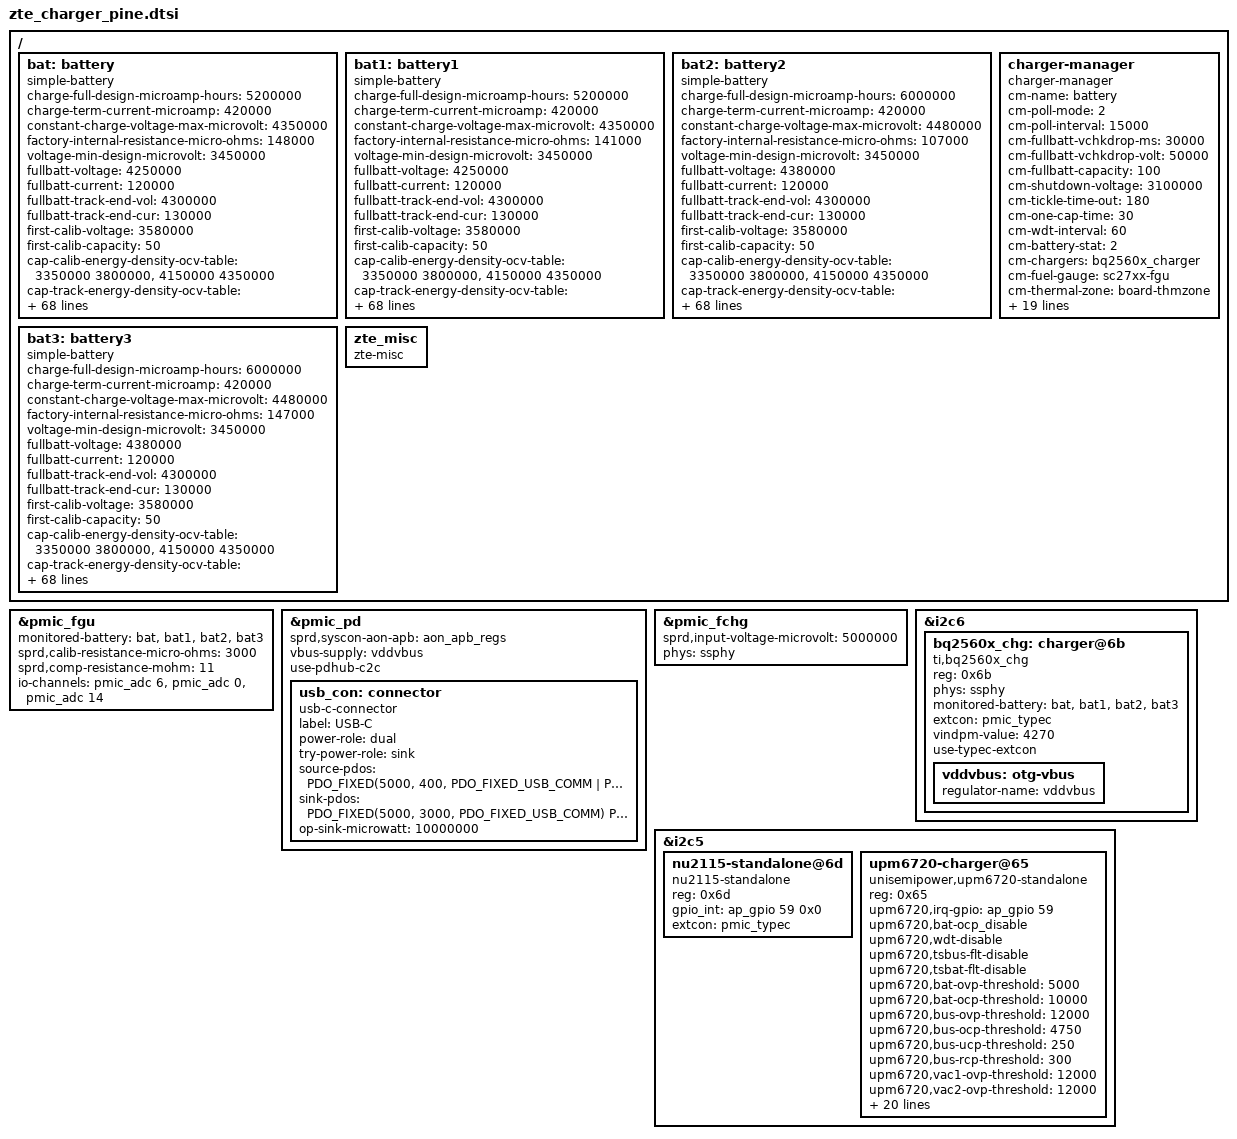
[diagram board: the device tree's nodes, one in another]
#include <dt-bindings/usb/pd.h>
#include <dt-bindings/mfd/sprd,ump9620-regs.h>
#include <dt-bindings/mfd/sprd,ump9620-mask.h>

/ {
	bat: battery {
		compatible = "simple-battery";
		charge-full-design-microamp-hours = <3690000>;
		charge-term-current-microamp = <120000>;
		constant-charge-voltage-max-microvolt = <4400000>;
		factory-internal-resistance-micro-ohms = <130000>;
		voltage-min-design-microvolt = <3450000>;
		fullbatt-voltage = <4350000>;
		fullbatt-current = <120000>;
		fullbatt-track-end-vol = <4345000>;
		fullbatt-track-end-cur = <130000>;
		first-calib-voltage = <3630000>;
		first-calib-capacity = <50>;

		cap-calib-energy-density-ocv-table = <3350000 3800000>, <4150000 4350000>;
		cap-track-energy-density-ocv-table = <3400000 3722000>;

		ocv-capacity-celsius = <20>;
		ocv-capacity-table-0 = <4380000 100>, <4317000 95>, <4258000 90>,
					<4200000 85>, <4145000 80>, <4092000 75>,
					<4047000 70>, <3990000 65>, <3955000 60>,
					<3900000 55>, <3861000 50>, <3834000 45>,
					<3813000 40>, <3796000 35>, <3783000 30>,
					<3770000 25>, <3752000 20>, <3730000 15>,
					<3698000 10>, <3687000 5>, <3400000 0>;
		voltage-temp-table = <1095000 800>, <986000 850>, <878000 900>,
					<775000 950>, <678000 1000>, <590000 1050>,
					<510000 1100>, <440000 1150>, <378000 1200>,
					<324000 1250>, <278000 1300>, <238000 1350>,
					<204000 1400>, <175000 1450>, <150000 1500>,
					<129000 1550>, <111000 1600>, <96000 1650>;
		capacity-temp-table = <45 100>, <25 100>, <10 98>, <0 93>, <(-10) 85>, <(-20) 64>;
		resistance-temp-table = <45 77>, <25 100>, <10 546>, <0 769>, <(-10) 892>, <(-20) 923>;

/*
		battery-internal-resistance-celsius = <(-20)>, <(-10)>, <0>, <10>,
			<25>, <35>, <45>, <55>;
		battery-internal-resistance-table-0 = <1224>, <1224>, <1140>,
			<1084>, <1034>, <1001>, <994>, <992>, <992>, <992>,
			<996>, <1002>, <1010>, <1024>, <1045>, <1072>, <1180>,
			<1393>, <1756>, <2461>, <4272>;
		battery-internal-resistance-table-1 = <893>, <893>, <818>, <767>,
			<743>, <705>, <685>, <684>, <678>, <675>, <672>, <673>,
			<679>, <691>, <709>, <734>, <765>, <799>, <839>, <899>,
			<1092>;
		battery-internal-resistance-table-2 = <407>, <407>, <402>, <423>,
			<429>, <428>, <409>, <416>, <408>, <395>, <390>, <390>,
			<393>, <398>, <405>, <416>, <431>, <452>, <492>, <585>,
			<730>;
		battery-internal-resistance-table-3 = <381>, <381>, <378>, <371>,
			<366>, <374>, <358>, <364>, <349>, <332>, <327>, <329>,
			<334>, <340>, <350>, <366>, <386>, <417>, <475>, <585>,
			<771>;
		battery-internal-resistance-table-4 = <182>, <182>, <179>, <179>,
			<179>, <181>, <182>, <195>, <194>, <173>, <164>, <164>,
			<167>, <171>, <175>, <174>, <172>, <179>, <187>, <244>,
			<311>;
		battery-internal-resistance-table-5 = <168>, <168>, <175>, <172>,
			<171>, <171>, <173>, <184>, <176>, <153>, <147>, <147>,
			<150>, <153>, <156>, <152>, <149>, <154>, <158>, <206>,
			<255>;
		battery-internal-resistance-table-6 = <123>, <123>, <122>, <122>,
			<123>, <126>, <130>, <138>, <143>, <120>, <115>, <116>,
			<119>, <124>, <129>, <120>, <117>, <119>, <117>, <139>,
			<156>;
		battery-internal-resistance-table-7 = <106>, <106>, <106>, <106>,
			<108>, <110>, <113>, <119>, <128>, <107>, <104>, <105>,
			<108>, <112>, <117>, <107>, <106>, <107>, <105>, <127>,
			<140>;
		battery-internal-resistance-ocv-table = <4339000>, <4276000>,
			<4221000>, <4169000>, <4118000>, <4072000>, <4022000>,
			<3983000>, <3942000>, <3892000>, <3857000>, <3833000>,
			<3813000>, <3797000>, <3783000>, <3766000>, <3746000>,
			<3723000>, <3693000>, <3680000>, <3439000>;
*/

		charge-sdp-current-microamp = <500000 500000>;
		charge-dcp-current-microamp = <1150000 3000000>;
		charge-cdp-current-microamp = <1150000 1150000>;
		charge-unknown-current-microamp = <500000 500000>;

		dcp-jeita-temp-table = <1000 1030 0 4400000>, <1150 1180 700000 4400000>,
			<1450 1420 1150000 4400000>, <1600 1570 700000 4100000>;
		sdp-jeita-temp-table = <1000 1030 0 4400000>, <1150 1180 500000 4400000>,
			<1450 1420 500000 4400000>, <1600 1570 500000 4100000>;
		cdp-jeita-temp-table = <1000 1030 0 4400000>, <1150 1180 700000 4400000>,
			<1450 1420 1150000 4400000>, <1600 1570 700000 4100000>;
		unknown-jeita-temp-table = <1000 1030 0 4400000>, <1150 1180 500000 4400000>,
			<1450 1420 500000 4400000>, <1600 1570 500000 4100000>;
		force-jeita-status = <2>;
	};

	bat1: battery1 {
		compatible = "simple-battery";
		charge-full-design-microamp-hours = <3690000>;
		charge-term-current-microamp = <120000>;
		constant-charge-voltage-max-microvolt = <4400000>;
		factory-internal-resistance-micro-ohms = <130000>;
		voltage-min-design-microvolt = <3450000>;
		fullbatt-voltage = <4350000>;
		fullbatt-current = <120000>;
		fullbatt-track-end-vol = <4345000>;
		fullbatt-track-end-cur = <130000>;
		first-calib-voltage = <3630000>;
		first-calib-capacity = <50>;

		cap-calib-energy-density-ocv-table = <3350000 3800000>, <4150000 4350000>;
		cap-track-energy-density-ocv-table = <3400000 3722000>;

		ocv-capacity-celsius = <20>;
		ocv-capacity-table-0 = <4380000 100>, <4317000 95>, <4258000 90>,
					<4200000 85>, <4145000 80>, <4092000 75>,
					<4047000 70>, <3990000 65>, <3955000 60>,
					<3900000 55>, <3861000 50>, <3834000 45>,
					<3813000 40>, <3796000 35>, <3783000 30>,
					<3770000 25>, <3752000 20>, <3730000 15>,
					<3698000 10>, <3687000 5>, <3400000 0>;
		voltage-temp-table = <1095000 800>, <986000 850>, <878000 900>,
					<775000 950>, <678000 1000>, <590000 1050>,
					<510000 1100>, <440000 1150>, <378000 1200>,
					<324000 1250>, <278000 1300>, <238000 1350>,
					<204000 1400>, <175000 1450>, <150000 1500>,
					<129000 1550>, <111000 1600>, <96000 1650>;
		capacity-temp-table = <45 100>, <25 100>, <10 98>, <0 93>, <(-10) 85>, <(-20) 64>;
		resistance-temp-table = <45 77>, <25 100>, <10 546>, <0 769>, <(-10) 892>, <(-20) 923>;

/*
		battery-internal-resistance-celsius = <(-20)>, <(-10)>, <0>, <10>,
			<25>, <35>, <45>, <55>;
		battery-internal-resistance-table-0 = <1224>, <1224>, <1140>,
			<1084>, <1034>, <1001>, <994>, <992>, <992>, <992>,
			<996>, <1002>, <1010>, <1024>, <1045>, <1072>, <1180>,
			<1393>, <1756>, <2461>, <4272>;
		battery-internal-resistance-table-1 = <893>, <893>, <818>, <767>,
			<743>, <705>, <685>, <684>, <678>, <675>, <672>, <673>,
			<679>, <691>, <709>, <734>, <765>, <799>, <839>, <899>,
			<1092>;
		battery-internal-resistance-table-2 = <407>, <407>, <402>, <423>,
			<429>, <428>, <409>, <416>, <408>, <395>, <390>, <390>,
			<393>, <398>, <405>, <416>, <431>, <452>, <492>, <585>,
			<730>;
		battery-internal-resistance-table-3 = <381>, <381>, <378>, <371>,
			<366>, <374>, <358>, <364>, <349>, <332>, <327>, <329>,
			<334>, <340>, <350>, <366>, <386>, <417>, <475>, <585>,
			<771>;
		battery-internal-resistance-table-4 = <182>, <182>, <179>, <179>,
			<179>, <181>, <182>, <195>, <194>, <173>, <164>, <164>,
			<167>, <171>, <175>, <174>, <172>, <179>, <187>, <244>,
			<311>;
		battery-internal-resistance-table-5 = <168>, <168>, <175>, <172>,
			<171>, <171>, <173>, <184>, <176>, <153>, <147>, <147>,
			<150>, <153>, <156>, <152>, <149>, <154>, <158>, <206>,
			<255>;
		battery-internal-resistance-table-6 = <123>, <123>, <122>, <122>,
			<123>, <126>, <130>, <138>, <143>, <120>, <115>, <116>,
			<119>, <124>, <129>, <120>, <117>, <119>, <117>, <139>,
			<156>;
		battery-internal-resistance-table-7 = <106>, <106>, <106>, <106>,
			<108>, <110>, <113>, <119>, <128>, <107>, <104>, <105>,
			<108>, <112>, <117>, <107>, <106>, <107>, <105>, <127>,
			<140>;
		battery-internal-resistance-ocv-table = <4339000>, <4276000>,
			<4221000>, <4169000>, <4118000>, <4072000>, <4022000>,
			<3983000>, <3942000>, <3892000>, <3857000>, <3833000>,
			<3813000>, <3797000>, <3783000>, <3766000>, <3746000>,
			<3723000>, <3693000>, <3680000>, <3439000>;
*/

		charge-sdp-current-microamp = <500000 500000>;
		charge-dcp-current-microamp = <1150000 3000000>;
		charge-cdp-current-microamp = <1150000 1150000>;
		charge-unknown-current-microamp = <500000 500000>;

		dcp-jeita-temp-table = <1000 1030 0 4400000>, <1150 1180 700000 4400000>,
			<1450 1420 1150000 4400000>, <1600 1570 700000 4100000>;
		sdp-jeita-temp-table = <1000 1030 0 4400000>, <1150 1180 500000 4400000>,
			<1450 1420 500000 4400000>, <1600 1570 500000 4100000>;
		cdp-jeita-temp-table = <1000 1030 0 4400000>, <1150 1180 700000 4400000>,
			<1450 1420 1150000 4400000>, <1600 1570 700000 4100000>;
		unknown-jeita-temp-table = <1000 1030 0 4400000>, <1150 1180 500000 4400000>,
			<1450 1420 500000 4400000>, <1600 1570 500000 4100000>;
		force-jeita-status = <2>;
	};

	bat2: battery2 {
		compatible = "simple-battery";
		charge-full-design-microamp-hours = <3690000>;
		charge-term-current-microamp = <120000>;
		constant-charge-voltage-max-microvolt = <4400000>;
		factory-internal-resistance-micro-ohms = <130000>;
		voltage-min-design-microvolt = <3450000>;
		fullbatt-voltage = <4350000>;
		fullbatt-current = <120000>;
		fullbatt-track-end-vol = <4345000>;
		fullbatt-track-end-cur = <130000>;
		first-calib-voltage = <3630000>;
		first-calib-capacity = <50>;

		cap-calib-energy-density-ocv-table = <3350000 3800000>, <4150000 4350000>;
		cap-track-energy-density-ocv-table = <3400000 3722000>;

		ocv-capacity-celsius = <20>;
		ocv-capacity-table-0 = <4380000 100>, <4317000 95>, <4258000 90>,
					<4200000 85>, <4145000 80>, <4092000 75>,
					<4047000 70>, <3990000 65>, <3955000 60>,
					<3900000 55>, <3861000 50>, <3834000 45>,
					<3813000 40>, <3796000 35>, <3783000 30>,
					<3770000 25>, <3752000 20>, <3730000 15>,
					<3698000 10>, <3687000 5>, <3400000 0>;
		voltage-temp-table = <1095000 800>, <986000 850>, <878000 900>,
					<775000 950>, <678000 1000>, <590000 1050>,
					<510000 1100>, <440000 1150>, <378000 1200>,
					<324000 1250>, <278000 1300>, <238000 1350>,
					<204000 1400>, <175000 1450>, <150000 1500>,
					<129000 1550>, <111000 1600>, <96000 1650>;
		capacity-temp-table = <45 100>, <25 100>, <10 98>, <0 93>, <(-10) 85>, <(-20) 64>;
		resistance-temp-table = <45 77>, <25 100>, <10 546>, <0 769>, <(-10) 892>, <(-20) 923>;

/*
		battery-internal-resistance-celsius = <(-20)>, <(-10)>, <0>, <10>,
			<25>, <35>, <45>, <55>;
		battery-internal-resistance-table-0 = <1224>, <1224>, <1140>,
			<1084>, <1034>, <1001>, <994>, <992>, <992>, <992>,
			<996>, <1002>, <1010>, <1024>, <1045>, <1072>, <1180>,
			<1393>, <1756>, <2461>, <4272>;
		battery-internal-resistance-table-1 = <893>, <893>, <818>, <767>,
			<743>, <705>, <685>, <684>, <678>, <675>, <672>, <673>,
			<679>, <691>, <709>, <734>, <765>, <799>, <839>, <899>,
			<1092>;
		battery-internal-resistance-table-2 = <407>, <407>, <402>, <423>,
			<429>, <428>, <409>, <416>, <408>, <395>, <390>, <390>,
			<393>, <398>, <405>, <416>, <431>, <452>, <492>, <585>,
			<730>;
		battery-internal-resistance-table-3 = <381>, <381>, <378>, <371>,
			<366>, <374>, <358>, <364>, <349>, <332>, <327>, <329>,
			<334>, <340>, <350>, <366>, <386>, <417>, <475>, <585>,
			<771>;
		battery-internal-resistance-table-4 = <182>, <182>, <179>, <179>,
			<179>, <181>, <182>, <195>, <194>, <173>, <164>, <164>,
			<167>, <171>, <175>, <174>, <172>, <179>, <187>, <244>,
			<311>;
		battery-internal-resistance-table-5 = <168>, <168>, <175>, <172>,
			<171>, <171>, <173>, <184>, <176>, <153>, <147>, <147>,
			<150>, <153>, <156>, <152>, <149>, <154>, <158>, <206>,
			<255>;
		battery-internal-resistance-table-6 = <123>, <123>, <122>, <122>,
			<123>, <126>, <130>, <138>, <143>, <120>, <115>, <116>,
			<119>, <124>, <129>, <120>, <117>, <119>, <117>, <139>,
			<156>;
		battery-internal-resistance-table-7 = <106>, <106>, <106>, <106>,
			<108>, <110>, <113>, <119>, <128>, <107>, <104>, <105>,
			<108>, <112>, <117>, <107>, <106>, <107>, <105>, <127>,
			<140>;
		battery-internal-resistance-ocv-table = <4339000>, <4276000>,
			<4221000>, <4169000>, <4118000>, <4072000>, <4022000>,
			<3983000>, <3942000>, <3892000>, <3857000>, <3833000>,
			<3813000>, <3797000>, <3783000>, <3766000>, <3746000>,
			<3723000>, <3693000>, <3680000>, <3439000>;
*/

		charge-sdp-current-microamp = <500000 500000>;
		charge-dcp-current-microamp = <1150000 3000000>;
		charge-cdp-current-microamp = <1150000 1150000>;
		charge-unknown-current-microamp = <500000 500000>;

		dcp-jeita-temp-table = <1000 1030 0 4400000>, <1150 1180 700000 4400000>,
			<1450 1420 1150000 4400000>, <1600 1570 700000 4100000>;
		sdp-jeita-temp-table = <1000 1030 0 4400000>, <1150 1180 500000 4400000>,
			<1450 1420 500000 4400000>, <1600 1570 500000 4100000>;
		cdp-jeita-temp-table = <1000 1030 0 4400000>, <1150 1180 700000 4400000>,
			<1450 1420 1150000 4400000>, <1600 1570 700000 4100000>;
		unknown-jeita-temp-table = <1000 1030 0 4400000>, <1150 1180 500000 4400000>,
			<1450 1420 500000 4400000>, <1600 1570 500000 4100000>;
		force-jeita-status = <2>;
	};

	bat3: battery3 {
		compatible = "simple-battery";
		charge-full-design-microamp-hours = <3690000>;
		charge-term-current-microamp = <120000>;
		constant-charge-voltage-max-microvolt = <4400000>;
		factory-internal-resistance-micro-ohms = <130000>;
		voltage-min-design-microvolt = <3450000>;
		fullbatt-voltage = <4350000>;
		fullbatt-current = <120000>;
		fullbatt-track-end-vol = <4345000>;
		fullbatt-track-end-cur = <130000>;
		first-calib-voltage = <3630000>;
		first-calib-capacity = <50>;

		cap-calib-energy-density-ocv-table = <3350000 3800000>, <4150000 4350000>;
		cap-track-energy-density-ocv-table = <3400000 3722000>;

		ocv-capacity-celsius = <20>;
		ocv-capacity-table-0 = <4380000 100>, <4317000 95>, <4258000 90>,
					<4200000 85>, <4145000 80>, <4092000 75>,
					<4047000 70>, <3990000 65>, <3955000 60>,
					<3900000 55>, <3861000 50>, <3834000 45>,
					<3813000 40>, <3796000 35>, <3783000 30>,
					<3770000 25>, <3752000 20>, <3730000 15>,
					<3698000 10>, <3687000 5>, <3400000 0>;
		voltage-temp-table = <1095000 800>, <986000 850>, <878000 900>,
					<775000 950>, <678000 1000>, <590000 1050>,
					<510000 1100>, <440000 1150>, <378000 1200>,
					<324000 1250>, <278000 1300>, <238000 1350>,
					<204000 1400>, <175000 1450>, <150000 1500>,
					<129000 1550>, <111000 1600>, <96000 1650>;
		capacity-temp-table = <45 100>, <25 100>, <10 98>, <0 93>, <(-10) 85>, <(-20) 64>;
		resistance-temp-table = <45 77>, <25 100>, <10 546>, <0 769>, <(-10) 892>, <(-20) 923>;

/*
		battery-internal-resistance-celsius = <(-20)>, <(-10)>, <0>, <10>,
			<25>, <35>, <45>, <55>;
		battery-internal-resistance-table-0 = <1224>, <1224>, <1140>,
			<1084>, <1034>, <1001>, <994>, <992>, <992>, <992>,
			<996>, <1002>, <1010>, <1024>, <1045>, <1072>, <1180>,
			<1393>, <1756>, <2461>, <4272>;
		battery-internal-resistance-table-1 = <893>, <893>, <818>, <767>,
			<743>, <705>, <685>, <684>, <678>, <675>, <672>, <673>,
			<679>, <691>, <709>, <734>, <765>, <799>, <839>, <899>,
			<1092>;
		battery-internal-resistance-table-2 = <407>, <407>, <402>, <423>,
			<429>, <428>, <409>, <416>, <408>, <395>, <390>, <390>,
			<393>, <398>, <405>, <416>, <431>, <452>, <492>, <585>,
			<730>;
		battery-internal-resistance-table-3 = <381>, <381>, <378>, <371>,
			<366>, <374>, <358>, <364>, <349>, <332>, <327>, <329>,
			<334>, <340>, <350>, <366>, <386>, <417>, <475>, <585>,
			<771>;
		battery-internal-resistance-table-4 = <182>, <182>, <179>, <179>,
			<179>, <181>, <182>, <195>, <194>, <173>, <164>, <164>,
			<167>, <171>, <175>, <174>, <172>, <179>, <187>, <244>,
			<311>;
		battery-internal-resistance-table-5 = <168>, <168>, <175>, <172>,
			<171>, <171>, <173>, <184>, <176>, <153>, <147>, <147>,
			<150>, <153>, <156>, <152>, <149>, <154>, <158>, <206>,
			<255>;
		battery-internal-resistance-table-6 = <123>, <123>, <122>, <122>,
			<123>, <126>, <130>, <138>, <143>, <120>, <115>, <116>,
			<119>, <124>, <129>, <120>, <117>, <119>, <117>, <139>,
			<156>;
		battery-internal-resistance-table-7 = <106>, <106>, <106>, <106>,
			<108>, <110>, <113>, <119>, <128>, <107>, <104>, <105>,
			<108>, <112>, <117>, <107>, <106>, <107>, <105>, <127>,
			<140>;
		battery-internal-resistance-ocv-table = <4339000>, <4276000>,
			<4221000>, <4169000>, <4118000>, <4072000>, <4022000>,
			<3983000>, <3942000>, <3892000>, <3857000>, <3833000>,
			<3813000>, <3797000>, <3783000>, <3766000>, <3746000>,
			<3723000>, <3693000>, <3680000>, <3439000>;
*/

		charge-sdp-current-microamp = <500000 500000>;
		charge-dcp-current-microamp = <1150000 3000000>;
		charge-cdp-current-microamp = <1150000 1150000>;
		charge-unknown-current-microamp = <500000 500000>;

		dcp-jeita-temp-table = <1000 1030 0 4400000>, <1150 1180 700000 4400000>,
			<1450 1420 1150000 4400000>, <1600 1570 700000 4100000>;
		sdp-jeita-temp-table = <1000 1030 0 4400000>, <1150 1180 500000 4400000>,
			<1450 1420 500000 4400000>, <1600 1570 500000 4100000>;
		cdp-jeita-temp-table = <1000 1030 0 4400000>, <1150 1180 700000 4400000>,
			<1450 1420 1150000 4400000>, <1600 1570 700000 4100000>;
		unknown-jeita-temp-table = <1000 1030 0 4400000>, <1150 1180 500000 4400000>,
			<1450 1420 500000 4400000>, <1600 1570 500000 4100000>;
		force-jeita-status = <2>;
	};

	charger-manager {
		compatible = "charger-manager";
		cm-name = "battery";

		cm-poll-mode = <2>;
		cm-poll-interval = <15000>;

		cm-fullbatt-vchkdrop-ms = <30000>;
		cm-fullbatt-vchkdrop-volt = <60000>;
		cm-fullbatt-capacity = <100>;
		
		/* drop voltage in microVolts to allow shutdown */
		cm-shutdown-voltage = <3100000>;
		/* when 99% of the time is exceeded, it will be forced to 100% */
		cm-tickle-time-out = <1500>;
		/* how much time to allow capacity change */
		cm-one-cap-time = <30>;
		/* the interval to feed charger watchdog */
		cm-wdt-interval = <60>;

		cm-battery-stat = <2>;

		cm-chargers = "fan54015_charger";
		cm-fuel-gauge = "sc27xx-fgu";
		cm-thermal-zone = "board-thmzone";

		/* in deci centigrade */
		cm-battery-cold = <200>;
		cm-battery-cold-in-minus;
		cm-battery-hot = <800>;
		cm-battery-temp-diff = <100>;

		/* Allow charging for 6hr */
		cm-charging-max = <21600000>;
		/* recovery charging after stop charging 45min */
		cm-discharging-max = <2700000>;

		/* when the safe charging voltage is exceeded, stop charging */
		cm-charge-voltage-max = <6500000>;
		/* drop voltage in microVolts to restart charging */
		cm-charge-voltage-drop = <700000>;
	};
};

&bat {
	charge-term-current-microamp = <420000>;
	constant-charge-voltage-max-microvolt = <4350000>;
	constant-charge-current-max-microamp = <4600000>;
	factory-internal-resistance-micro-ohms = <148000>;
	voltage-min-design-microvolt = <3450000>;
	fast-charge-threshold-microvolt = <4100000>;
	fullbatt-voltage = <4250000>;		/* minus 100mV */
	fullbatt-current = <120000>;		/* not used */
	fullbatt-track-end-vol = <4300000>;
	fullbatt-track-end-cur = <130000>;
	first-calib-voltage = <3580000>;
	first-calib-capacity = <50>;

	ir-cv-offset-microvolt = <100000>;
	ir-rc-micro-ohms = <20000>;
	ir-us-upper-limit-microvolt = <4500000>;

	batt-id-list = <2 390 121 270>;  /*weike haopeng/tianmao 5200mAH haopeng/tiaomao 6000mAH kohm*/
	batt-id-ref-vol = <1875>; /* mV */
	charge-full-design-microamp-hours = <5200000>;
	/*Minimum Capacity 5200*0.9 = 4680 5200*0.94 = 4888 5200*0.95 = 4940 5200*0.96 = 4992,we use *0.96 */
	charge-full-microamp-hours = <4992000>;
	fullbatt-advance-level = <986>;

	ocv-capacity-celsius = <25>;
	ocv-capacity-table-0 = <4292000 100>, <4233000 95>, <4180000 90>,
				<4129000 85>, <4080000 80>, <4039000 75>,
				<3981000 70>, <3956000 65>, <3920000 60>,
				<3866000 55>, <3839000 50>, <3817000 45>,
				<3800000 40>, <3786000 35>, <3775000 30>,
				<3756000 25>, <3740000 20>, <3715000 15>,
				<3688000 10>, <3676000 5>, <3400000 0>;
	/* NTC 100k, Vref 1850mV, R pull-up 110K, R pull-down 1000k */
	voltage-temp-table = <1591473 750>, <1555286 800>, <1512176 850>,
				<1459276 900>, <1395886 950>, <1322179 1000>,
				<1238711 1050>, <1147116 1100>, <1049658 1150>,
				<949081 1200>, <848416 1250>, <750447 1300>,
				<657569 1350>, <571537 1400>, <493518 1450>,
				<423845 1500>, <362641 1550>, <309430 1600>,
				<263582 1650>, <221438 1700>, <188468 1750>;
	capacity-temp-table = <25 100>, <10 99>, <0 96>, <(-10) 82>, <(-20) 52>; /* 93-->99, 80-->96, 63-->82 */
	resistance-temp-table = <25 100>, <10 239>, <0 883>, <(-10) 935>, <(-20) 1141>;

	/*sqc plan useless data*/
	charge-sdp-current-microamp = <700000 500000>;
	charge-dcp-current-microamp = <3400000 2000000>;
	charge-cdp-current-microamp = <3400000 1500000>;
	charge-unknown-current-microamp = <1000000 1000000>;
	charge-fchg-current-microamp = <1950000 2000000>;
	charge-flash-current-microamp = <1950000 2000000>;

	dcp-jeita-temp-table = <1000 1030 0 4350000>,
				<1100 1130 1500000 4350000>,
				<1200 1230 1500000 4350000>,
				<1450 1420 3600000 4350000>,
				<1550 1520 1800000 4100000>;
	sdp-jeita-temp-table = <1000 1030 0 4350000>,
				<1100 1130 1500000 4350000>,
				<1200 1230 1500000 4350000>,
				<1450 1420 3600000 4350000>,
				<1550 1520 1800000 4100000>;
	cdp-jeita-temp-table = <1000 1030 0 4350000>,
				<1100 1130 1500000 4350000>,
				<1200 1230 1500000 4350000>,
				<1450 1420 3600000 4350000>,
				<1550 1520 1800000 4100000>;
	unknown-jeita-temp-table = <1000 1030 0 4350000>,
				<1100 1130 1500000 4350000>,
				<1200 1230 1500000 4350000>,
				<1450 1420 3600000 4350000>,
				<1550 1520 1800000 4100000>;
	fchg-jeita-temp-table = <1000 1030 0 4350000>,
				<1100 1130 1500000 4350000>,
				<1200 1230 1500000 4350000>,
				<1450 1420 3600000 4350000>,
				<1550 1520 1800000 4100000>;
	flash-jeita-temp-table = <1000 1030 0 4350000>,
				<1100 1130 1500000 4350000>,
				<1200 1230 1500000 4350000>,
				<1450 1420 3600000 4350000>,
				<1550 1520 1800000 4350000>;
};

&bat1 {
	charge-term-current-microamp = <420000>;
	constant-charge-voltage-max-microvolt = <4350000>;
	constant-charge-current-max-microamp = <4600000>;
	factory-internal-resistance-micro-ohms = <141000>;
	voltage-min-design-microvolt = <3450000>;
	fast-charge-threshold-microvolt = <4100000>;
	fullbatt-voltage = <4250000>;		/* minus 100mV */
	fullbatt-current = <120000>;		/* not used */
	fullbatt-track-end-vol = <4300000>;
	fullbatt-track-end-cur = <130000>;
	first-calib-voltage = <3580000>;
	first-calib-capacity = <50>;

	ir-cv-offset-microvolt = <100000>;
	ir-rc-micro-ohms = <20000>;
	ir-us-upper-limit-microvolt = <4500000>;

	batt-id-list = <2 390 121 270>;  /*weike haopeng/tianmao 5200mAH haopeng/tiaomao 6000mAH kohm*/
	batt-id-ref-vol = <1875>; /* mV */
	charge-full-design-microamp-hours = <5200000>;
	/*Minimum Capacity 5200*0.9 = 4680 5200*0.94 = 4888 5200*0.95 = 4940 5200*0.96 = 4992,we use *0.95 */
	charge-full-microamp-hours = <4940000>;
	fullbatt-advance-level = <986>;

	ocv-capacity-celsius = <25>;
	ocv-capacity-table-0 = <4294000 100>, <4233000 95>, <4179000 90>,
				<4127000 85>, <4078000 80>, <4033000 75>,
				<3980000 70>, <3952000 65>, <3915000 60>,
				<3863000 55>, <3835000 50>, <3815000 45>,
				<3799000 40>, <3786000 35>, <3775000 30>,
				<3758000 25>, <3740000 20>, <3715000 15>,
				<3688000 10>, <3677000 5>, <3400000 0>;
	/* NTC 100k, Vref 1850mV, R pull-up 110K, R pull-down 1000k */
	voltage-temp-table = <1591473 750>, <1555286 800>, <1512176 850>,
				<1459276 900>, <1395886 950>, <1322179 1000>,
				<1238711 1050>, <1147116 1100>, <1049658 1150>,
				<949081 1200>, <848416 1250>, <750447 1300>,
				<657569 1350>, <571537 1400>, <493518 1450>,
				<423845 1500>, <362641 1550>, <309430 1600>,
				<263582 1650>, <221438 1700>, <188468 1750>;
	capacity-temp-table = <25 100>, <10 99>, <0 96>, <(-10) 72>, <(-20) 58>;
	resistance-temp-table = <25 100>, <10 163>, <0 590>, <(-10) 839>, <(-20) 934>;

	/*sqc plan useless data*/
	charge-sdp-current-microamp = <700000 500000>;
	charge-dcp-current-microamp = <3400000 2000000>;
	charge-cdp-current-microamp = <3400000 1500000>;
	charge-unknown-current-microamp = <1000000 1000000>;
	charge-fchg-current-microamp = <1950000 2000000>;
	charge-flash-current-microamp = <1950000 2000000>;

	dcp-jeita-temp-table = <1000 1030 0 4350000>,
				<1100 1130 1500000 4350000>,
				<1200 1230 1500000 4350000>,
				<1450 1420 3600000 4350000>,
				<1550 1520 1800000 4100000>;
	sdp-jeita-temp-table = <1000 1030 0 4350000>,
				<1100 1130 1500000 4350000>,
				<1200 1230 1500000 4350000>,
				<1450 1420 3600000 4350000>,
				<1550 1520 1800000 4100000>;
	cdp-jeita-temp-table = <1000 1030 0 4350000>,
				<1100 1130 1500000 4350000>,
				<1200 1230 1500000 4350000>,
				<1450 1420 3600000 4350000>,
				<1550 1520 1800000 4100000>;
	unknown-jeita-temp-table = <1000 1030 0 4350000>,
				<1100 1130 1500000 4350000>,
				<1200 1230 1500000 4350000>,
				<1450 1420 3600000 4350000>,
				<1550 1520 1800000 4100000>;
	fchg-jeita-temp-table = <1000 1030 0 4350000>,
				<1100 1130 1500000 4350000>,
				<1200 1230 1500000 4350000>,
				<1450 1420 3600000 4350000>,
				<1550 1520 1800000 4100000>;
	flash-jeita-temp-table = <1000 1030 0 4350000>,
				<1100 1130 1500000 4350000>,
				<1200 1230 1500000 4350000>,
				<1450 1420 3600000 4350000>,
				<1550 1520 1800000 4350000>;
};

&bat2 {
	charge-term-current-microamp = <420000>;
	constant-charge-voltage-max-microvolt = <4480000>;
	constant-charge-current-max-microamp = <5400000>;
	factory-internal-resistance-micro-ohms = <107000>;
	voltage-min-design-microvolt = <3450000>;
	fast-charge-threshold-microvolt = <4100000>;
	fullbatt-voltage = <4380000>;		/* minus 100mV */
	fullbatt-current = <120000>;		/* not used */
	fullbatt-track-end-vol = <4300000>;
	fullbatt-track-end-cur = <130000>;
	first-calib-voltage = <3580000>;
	first-calib-capacity = <50>;

	ir-cv-offset-microvolt = <100000>;
	ir-rc-micro-ohms = <20000>;
	ir-us-upper-limit-microvolt = <4500000>;

	batt-id-list = <2 390 121 270>;  /*weike haopeng/tianmao 5200mAH haopeng/tiaomao 6000mAH kohm*/
	batt-id-ref-vol = <1875>; /* mV */
	charge-full-design-microamp-hours = <6000000>;
	/*Minimum Capacity 6000*0.9 = 5400 6000*0.94 = 5640 6000*0.95 = 5700 6000*0.96 = 5760,we use *0.96 */
	charge-full-microamp-hours = <5760000>;
	fullbatt-advance-level = <1000>;

	ocv-capacity-celsius = <25>;
	ocv-capacity-table-0 = <4430000 100>, <4370000 95>, <4315000 90>,
				<4256000 85>, <4196000 80>, <4138000 75>,
				<4083000 70>, <4033000 65>, <3987000 60>,
				<3931000 55>, <3883000 50>, <3854000 45>,
				<3830000 40>, <3810000 35>, <3794000 30>,
				<3764000 25>, <3740000 20>, <3715000 15>,
				<3683000 10>, <3673000 5>, <3400000 0>;
	/* NTC 100k, Vref 1850mV, R pull-up 110K, R pull-down 1000k */
	voltage-temp-table = <1591473 750>, <1555286 800>, <1512176 850>,
				<1459276 900>, <1395886 950>, <1322179 1000>,
				<1238711 1050>, <1147116 1100>, <1049658 1150>,
				<949081 1200>, <848416 1250>, <750447 1300>,
				<657569 1350>, <571537 1400>, <493518 1450>,
				<423845 1500>, <362641 1550>, <309430 1600>,
				<263582 1650>, <221438 1700>, <188468 1750>;
	capacity-temp-table = <25 100>, <10 98>, <0 85>, <(-10) 63>, <(-20) 52>;
	resistance-temp-table = <25 100>, <10 179>, <0 1057>, <(-10) 1125>, <(-20) 1193>;

	/*sqc plan useless data*/
	charge-sdp-current-microamp = <700000 500000>;
	charge-dcp-current-microamp = <3400000 2000000>;
	charge-cdp-current-microamp = <3400000 1500000>;
	charge-unknown-current-microamp = <1000000 1000000>;
	charge-fchg-current-microamp = <1950000 2000000>;
	charge-flash-current-microamp = <1950000 2000000>;

	dcp-jeita-temp-table = <1000 1030 0 4480000>,
				<1100 1130 1800000 4480000>,
				<1200 1230 1800000 4480000>,
				<1450 1420 4200000 4480000>,
				<1550 1520 2100000 4100000>;
	sdp-jeita-temp-table = <1000 1030 0 4480000>,
				<1100 1130 1800000 4480000>,
				<1200 1230 1800000 4480000>,
				<1450 1420 4200000 4480000>,
				<1550 1520 2100000 4100000>;
	cdp-jeita-temp-table = <1000 1030 0 4480000>,
				<1100 1130 1800000 4480000>,
				<1200 1230 1800000 4480000>,
				<1450 1420 4200000 4480000>,
				<1550 1520 2100000 4100000>;
	unknown-jeita-temp-table = <1000 1030 0 4480000>,
				<1100 1130 1800000 4480000>,
				<1200 1230 1800000 4480000>,
				<1450 1420 4200000 4480000>,
				<1550 1520 2100000 4100000>;
	fchg-jeita-temp-table = <1000 1030 0 4480000>,
				<1100 1130 1800000 4480000>,
				<1200 1230 1800000 4480000>,
				<1450 1420 4200000 4480000>,
				<1550 1520 2100000 4100000>;
	flash-jeita-temp-table = <1000 1030 0 4480000>,
				<1100 1130 1800000 4480000>,
				<1200 1230 1800000 4480000>,
				<1450 1420 4200000 4480000>,
				<1550 1520 2100000 4100000>;
};

&bat3 {
	charge-term-current-microamp = <420000>;
	constant-charge-voltage-max-microvolt = <4480000>;
	constant-charge-current-max-microamp = <5400000>;
	factory-internal-resistance-micro-ohms = <147000>;
	voltage-min-design-microvolt = <3450000>;
	fast-charge-threshold-microvolt = <4100000>;
	fullbatt-voltage = <4380000>;		/* minus 100mV */
	fullbatt-current = <120000>;		/* not used */
	fullbatt-track-end-vol = <4300000>;
	fullbatt-track-end-cur = <130000>;
	first-calib-voltage = <3580000>;
	first-calib-capacity = <50>;

	ir-cv-offset-microvolt = <100000>;
	ir-rc-micro-ohms = <20000>;
	ir-us-upper-limit-microvolt = <4500000>;

	batt-id-list = <2 390 121 270>;  /*weike haopeng/tianmao 5200mAH haopeng/tiaomao 6000mAH kohm*/
	batt-id-ref-vol = <1875>; /* mV */
	charge-full-design-microamp-hours = <6000000>;
	/*Minimum Capacity 6000*0.9 = 5400 6000*0.94 = 5640 6000*0.95 = 5700 6000*0.96 = 5760,we use *0.95 */
	charge-full-microamp-hours = <5700000>;
	fullbatt-advance-level = <970>;

	ocv-capacity-celsius = <25>;
	ocv-capacity-table-0 = <4420000 100>, <4364000 95>, <4311000 90>,
				<4253000 85>, <4193000 80>, <4136000 75>,
				<4081000 70>, <4031000 65>, <3983000 60>,
				<3919000 55>, <3881000 50>, <3852000 45>,
				<3828000 40>, <3809000 35>, <3793000 30>,
				<3769000 25>, <3747000 20>, <3722000 15>,
				<3692000 10>, <3680000 5>, <3400000 0>;
	/* NTC 100k, Vref 1850mV, R pull-up 110K, R pull-down 1000k */
	voltage-temp-table = <1591473 750>, <1555286 800>, <1512176 850>,
				<1459276 900>, <1395886 950>, <1322179 1000>,
				<1238711 1050>, <1147116 1100>, <1049658 1150>,
				<949081 1200>, <848416 1250>, <750447 1300>,
				<657569 1350>, <571537 1400>, <493518 1450>,
				<423845 1500>, <362641 1550>, <309430 1600>,
				<263582 1650>, <221438 1700>, <188468 1750>;
	capacity-temp-table = <25 100>, <10 95>, <0 86>, <(-10) 59>, <(-20) 47>;
	resistance-temp-table = <25 100>, <10 213>, <0 790>, <(-10) 903>, <(-20) 1025>;

	/*sqc plan useless data*/
	charge-sdp-current-microamp = <700000 500000>;
	charge-dcp-current-microamp = <3400000 2000000>;
	charge-cdp-current-microamp = <3400000 1500000>;
	charge-unknown-current-microamp = <1000000 1000000>;
	charge-fchg-current-microamp = <1950000 2000000>;
	charge-flash-current-microamp = <1950000 2000000>;

	dcp-jeita-temp-table = <1000 1030 0 4480000>,
				<1100 1130 1800000 4480000>,
				<1200 1230 1800000 4480000>,
				<1450 1420 4200000 4480000>,
				<1550 1520 2100000 4100000>;
	sdp-jeita-temp-table = <1000 1030 0 4480000>,
				<1100 1130 1800000 4480000>,
				<1200 1230 1800000 4480000>,
				<1450 1420 4200000 4480000>,
				<1550 1520 2100000 4100000>;
	cdp-jeita-temp-table = <1000 1030 0 4480000>,
				<1100 1130 1800000 4480000>,
				<1200 1230 1800000 4480000>,
				<1450 1420 4200000 4480000>,
				<1550 1520 2100000 4100000>;
	unknown-jeita-temp-table = <1000 1030 0 4480000>,
				<1100 1130 1800000 4480000>,
				<1200 1230 1800000 4480000>,
				<1450 1420 4200000 4480000>,
				<1550 1520 2100000 4100000>;
	fchg-jeita-temp-table = <1000 1030 0 4480000>,
				<1100 1130 1800000 4480000>,
				<1200 1230 1800000 4480000>,
				<1450 1420 4200000 4480000>,
				<1550 1520 2100000 4100000>;
	flash-jeita-temp-table = <1000 1030 0 4480000>,
				<1100 1130 1800000 4480000>,
				<1200 1230 1800000 4480000>,
				<1450 1420 4200000 4480000>,
				<1550 1520 2100000 4100000>;
};

&pmic_fgu {
	monitored-battery = <&bat &bat1 &bat2 &bat3>;
	sprd,calib-resistance-micro-ohms = <3000>;
	sprd,comp-resistance-mohm = <11>;
	io-channels = <&pmic_adc 6>, <&pmic_adc 0>, <&pmic_adc 14>;
	io-channel-names = "adc-batt-id", "bat-temp", "charge-vol";
};

&pmic_pd {
	status = "okay";
	sprd,syscon-aon-apb = <&aon_apb_regs>;
	vbus-supply = <&vddvbus>;
	use-pdhub-c2c;
	usb_con: connector {
		compatible = "usb-c-connector";
		label = "USB-C";
		power-role = "dual";
		try-power-role = "sink";
		source-pdos = <PDO_FIXED(5000, 400, PDO_FIXED_USB_COMM |
				PDO_FIXED_DUAL_ROLE | PDO_FIXED_DATA_SWAP)>;
		sink-pdos = <PDO_FIXED(5000, 3000, PDO_FIXED_USB_COMM)
				PDO_PPS_APDO(3300, 11000, 6000)>;
		op-sink-microwatt = <10000000>;
	};
};

&pmic_fchg {
	sprd,input-voltage-microvolt = <5000000>;
	phys = <&ssphy>;
	status = "okay";
};
/ {
	charger-manager {
		cm-fullbatt-vchkdrop-volt = <50000>;
		/* in deci centigrade */
		cm-battery-cold = <0>;
		cm-battery-hot = <550>;
		cm-battery-temp-diff = <30>;
		cm-tickle-time-out = <180>;

		/* sprd_fchg parameter */
		sprd,support-fchg;
		sprd,support-pd-pps;
		sprd,pd-fixed-max-microwatt = <18000000>;
		use-typec-extcon;
		pd-extcon-enable;
		extcon = <&pmic_typec>, <&pmic_pd>;

		cm-chargers = "bq2560x_charger";
		cm-hardware-psy = "bq2560x_charger";
		zte-cm-hardware-psy = "zte_bq2560x_charger";
		zte-cm-fuel-gauge = "zte-fgu";
		monitored-battery = <&bat &bat1 &bat2 &bat3>;
		phys = <&ssphy>;
	};

	zte_misc: zte_misc {
		status = "okay";
		compatible = "zte-misc";
	};
};

&i2c6 {
	status = "okay";
	bq2560x_chg: charger@6b {
		compatible = "ti,bq2560x_chg";
		reg = <0x6b>;
		phys = <&ssphy>;
		monitored-battery = <&bat &bat1 &bat2 &bat3>;
		extcon = <&pmic_typec>;
		vindpm-value = <4270>;
		use-typec-extcon;
		vddvbus:otg-vbus {
			regulator-name = "vddvbus";
		};
	};
};

&i2c5 {
	status = "okay";
	nu2115-standalone@6d {
		compatible = "nu2115-standalone";
		status = "okay";
		reg = <0x6d>;
		gpio_int = <&ap_gpio 59 0x0>;
		extcon = <&pmic_typec>;
	};

	upm6720-charger@65{
		status = "okay";
		compatible = "unisemipower,upm6720-standalone";
		reg = <0x65>;
		upm6720,irq-gpio = <&ap_gpio 59 0x0>;

		upm6720,bat-ocp_disable;
		upm6720,wdt-disable;
		upm6720,tsbus-flt-disable;
		upm6720,tsbat-flt-disable;

		upm6720,bat-ovp-threshold = <5000>;			/* unit: 1mV */
		upm6720,bat-ocp-threshold = <10000>;		/* unit: 1mA */
		upm6720,bus-ovp-threshold = <12000>;		/* unit: 1mV */
		upm6720,bus-ocp-threshold = <4750>;			/* unit: 1mA */
		upm6720,bus-ucp-threshold = <250>;			/* unit: 1mA */
		upm6720,bus-rcp-threshold = <300>;			/* unit: 1mA */
		upm6720,vac1-ovp-threshold = <12000>;		/* unit: 1mV */
		upm6720,vac2-ovp-threshold = <12000>;		/* unit: 1mV */
		upm6720,vout-ovp-threshold = <5000>;		/* unit: 1mV */

		upm6720,bat-ovp-alm-threshold = <4510>;		/* unit: 1mV */
		upm6720,bat-ocp-alm-threshold = <8000>;	/* unit: 1mA */
		upm6720,bat-ucp-alm-threshold = <2000>;		/* unit: 1mA */
		upm6720,bus-ovp-alm-threshold = <8900>;	/* unit: 1mV */
		upm6720,bus-ocp-alm-threshold = <4000>;		/* unit: 1mA */
		upm6720,tdie-alm-threshold = <125>;		/* unit: 1?? */

		upm6720,sense-resistor-mohm = <5>;	/* unit: 1mohm */
		upm6720,ss-timeout = <10000>;		/* unit: 1ms */
		upm6720,wdt-set = <30000>;		/* unit: 1ms */
		upm6720,chg-config-1 = <1>;
		upm6720,fsw-set = <500>;
		upm6720,freq-shift = <0>;
		upm6720,ibus-ucp-fall-dg-sel = <0>;

		upm6720,adc-enable;
		upm6720,adc-rate = <0>;
		upm6720,adc-avg = <0>;
		upm6720,adc-avg-init = <0>;
		upm6720,adc-sample-bit = <0>;

		extcon = <&pmic_typec>;
	};

};

#include "../bat_setting/battery_protect_policy_080509200178.dtsi"
